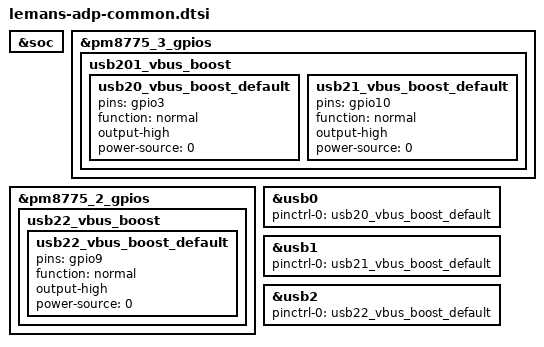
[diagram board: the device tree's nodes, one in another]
#include "lemans-pmic-overlay.dtsi"
#include "lemans-thermal-overlay.dtsi"

&soc {

};

&pm8775_3_gpios {
	usb201_vbus_boost {
		usb20_vbus_boost_default: usb20_vbus_boost_default {
			pins = "gpio3";
			function = "normal";
			output-high;
			power-source = <0>;
		};

		usb21_vbus_boost_default: usb21_vbus_boost_default {
			pins = "gpio10";
			function = "normal";
			output-high;
			power-source = <0>;
		};
	};
};

&pm8775_2_gpios {
	usb22_vbus_boost {
		usb22_vbus_boost_default: usb22_vbus_boost_default {
			pins = "gpio9";
			function = "normal";
			output-high;
			power-source = <0>;
		};
	};
};

&usb0 {
	pinctrl-names = "default";
	pinctrl-0 = <&usb20_vbus_boost_default>;
};

&usb1 {
	pinctrl-names = "default";
	pinctrl-0 = <&usb21_vbus_boost_default>;
};

&usb2 {
	pinctrl-names = "default";
	pinctrl-0 = <&usb22_vbus_boost_default>;
};
